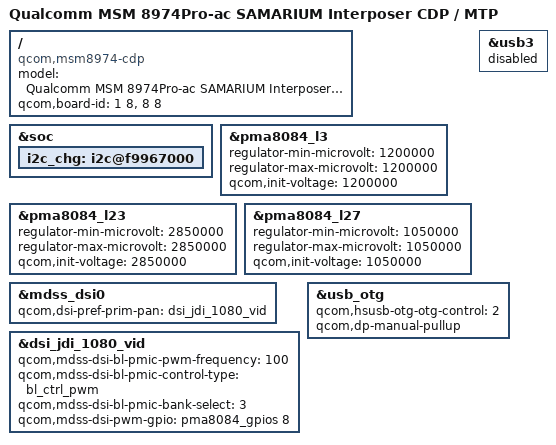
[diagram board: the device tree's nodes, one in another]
/* Copyright (c) 2013, The Linux Foundation. All rights reserved.
 *
 * This program is free software; you can redistribute it and/or modify
 * it under the terms of the GNU General Public License version 2 and
 * only version 2 as published by the Free Software Foundation.
 *
 * This program is distributed in the hope that it will be useful,
 * but WITHOUT ANY WARRANTY; without even the implied warranty of
 * MERCHANTABILITY or FITNESS FOR A PARTICULAR PURPOSE.  See the
 * GNU General Public License for more details.
 */

/dts-v1/;

/include/ "msm8974pro-ac.dtsi"
&soc {
	i2c_chg: i2c@f9967000 { /* BLSP#11 */
	};
};
/include/ "msmsamarium-cdp.dtsi"
/include/ "msmsamarium-camera-sensor-cdp-interposer.dtsi"

/ {
        model = "Qualcomm MSM 8974Pro-ac SAMARIUM Interposer CDP / MTP";
        compatible = "qcom,msm8974-cdp", "qcom,msm8974", "qcom,cdp";
        qcom,board-id = <1 8>, <8 8>;
};

&pma8084_l3 {
	regulator-min-microvolt = <1200000>;
	regulator-max-microvolt = <1200000>;
	qcom,init-voltage = <1200000>;
};

&pma8084_l23 {
	regulator-min-microvolt = <2850000>;
	regulator-max-microvolt = <2850000>;
	qcom,init-voltage = <2850000>;
};

&pma8084_l27 {
	regulator-min-microvolt = <1050000>;
	regulator-max-microvolt = <1050000>;
	qcom,init-voltage = <1050000>;
};

&mdss_dsi0 {
	qcom,dsi-pref-prim-pan = <&dsi_jdi_1080_vid>;
};

&dsi_jdi_1080_vid {
	qcom,mdss-dsi-bl-pmic-pwm-frequency = <100>;
	qcom,mdss-dsi-bl-pmic-control-type = "bl_ctrl_pwm";
	qcom,mdss-dsi-bl-pmic-bank-select = <3>;
	qcom,mdss-dsi-pwm-gpio = <&pma8084_gpios 8 0>;
};

&usb3 {
	status = "disabled";
};

&usb_otg {
	status = "ok";
	qcom,hsusb-otg-otg-control = <2>;
	qcom,dp-manual-pullup;
};
